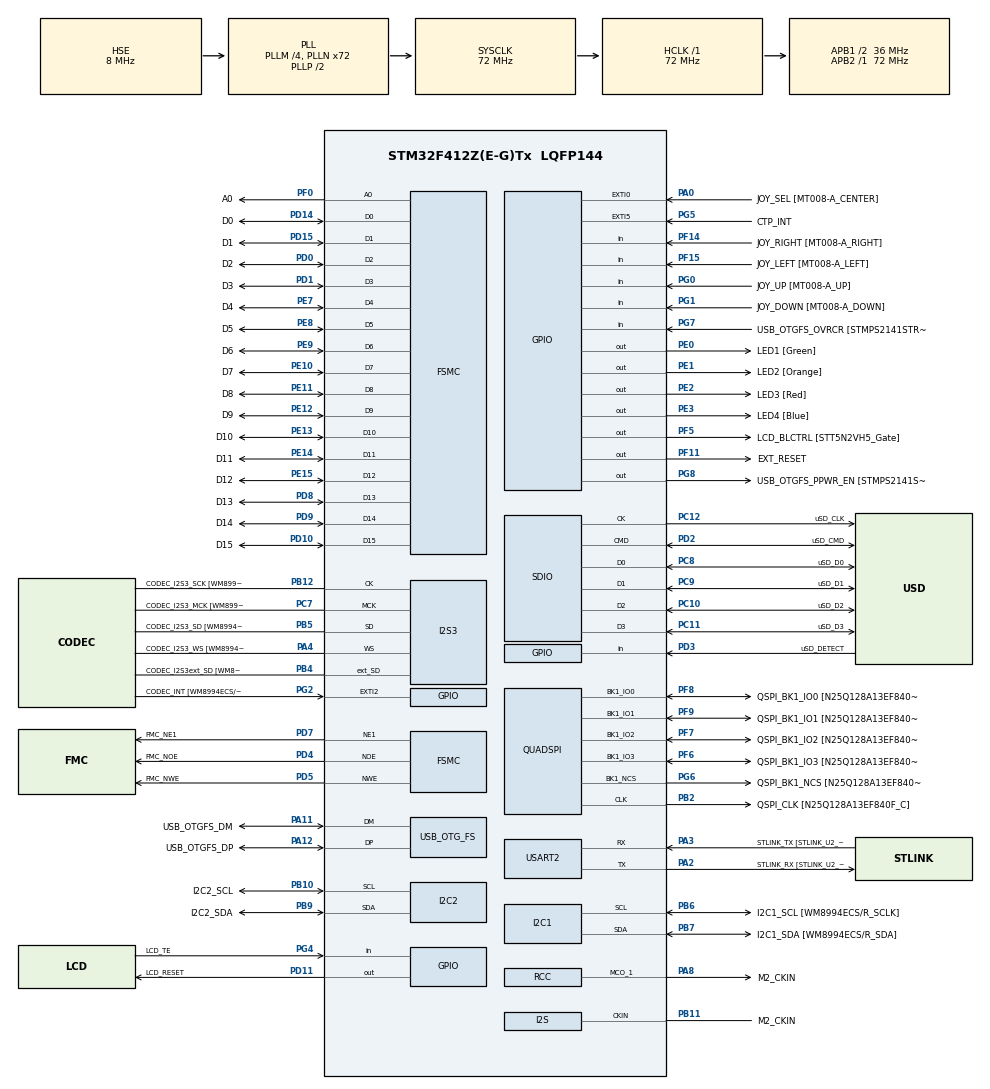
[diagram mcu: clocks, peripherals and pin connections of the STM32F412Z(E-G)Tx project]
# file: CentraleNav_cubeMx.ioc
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I2S3.AudioFreq=I2S_AUDIOFREQ_32K
I2S3.ErrorAudioFreq=1.72 %
I2S3.FullDuplexMode=I2S_FULLDUPLEXMODE_ENABLE
I2S3.Instance=SPI$Index
I2S3.RealAudioFreq=32.552 KHz
I2S3.VirtualMode=I2S_MODE_MASTER
Mcu.Family=STM32F4
Mcu.Name=STM32F412Z(E-G)Tx
Mcu.Package=LQFP144
NVIC.OTG_FS_IRQn=true\:0\:0\:false\:false\:true\:true\:true
NVIC.PriorityGroup=NVIC_PRIORITYGROUP_4
NVIC.TIM1_TRG_COM_TIM11_IRQn=true\:0\:0\:false\:false\:true\:true\:true
NVIC.TIM8_BRK_TIM12_IRQn=true\:0\:0\:false\:false\:true\:true\:true
NVIC.TIM8_UP_TIM13_IRQn=true\:0\:0\:false\:false\:true\:true\:true
PA0.GPIO_Label=JOY_SEL [MT008-A_CENTER]
PA0.Signal=GPXTI0
PA10.GPIO_Label=USB_OTGFS_ID
PA10.Signal=USB_OTG_FS_ID
PA11.GPIO_Label=USB_OTGFS_DM
PA11.Mode=Host_Only
PA11.Signal=USB_OTG_FS_DM
PA12.GPIO_Label=USB_OTGFS_DP
PA12.Mode=Host_Only
PA12.Signal=USB_OTG_FS_DP
PA13.GPIO_Label=SWDIO
PA13.Mode=Serial_Wire
PA13.Signal=SYS_JTMS-SWDIO
PA14.GPIO_Label=SWCLK
PA14.Mode=Serial_Wire
PA14.Signal=SYS_JTCK-SWCLK
PA2.GPIO_Label=STLINK_RX [STLINK_U2_RX]
PA2.Mode=Asynchronous
PA2.Signal=USART2_TX
PA3.GPIO_Label=STLINK_TX [STLINK_U2_TX]
PA3.Mode=Asynchronous
PA3.Signal=USART2_RX
PA4.GPIO_Label=CODEC_I2S3_WS [WM8994ECS/R_LRCLK1]
PA4.Mode=Full_Duplex_Master
PA4.Signal=I2S3_WS
PA8.GPIO_Label=M2_CKIN
PA8.Mode=Clock-out-1
PA8.Signal=RCC_MCO_1
PA9.GPIO_Label=USB_OTGFS_VBUS
PA9.Signal=USB_OTG_FS_VBUS
PB1.GPIO_Label=DFSDM_DATIN0 [MP34DT01TR_DOUT]
PB1.Signal=S_DATAIN0DFSDM1
PB10.GPIO_Label=I2C2_SCL
PB10.Mode=I2C
PB10.Signal=I2C2_SCL
PB11.GPIO_Label=M2_CKIN
PB11.Mode=Audio_ClockIn
PB11.Signal=I2S_CKIN
PB12.GPIO_Label=CODEC_I2S3_SCK [WM8994ECS/R_BCLK1]
PB12.Mode=Full_Duplex_Master
PB12.Signal=I2S3_CK
PB2.GPIO_Label=QSPI_CLK [N25Q128A13EF840F_C]
PB2.Mode=Single Bank 1
PB2.Signal=QUADSPI_CLK
PB3.GPIO_Label=SWO
PB3.Signal=SYS_JTDO-SWO
PB4.GPIO_Label=CODEC_I2S3ext_SD [WM8994ECS/R_ACDAT1]
PB4.Mode=Full_Duplex_Master
PB4.Signal=I2S3_ext_SD
PB5.GPIO_Label=CODEC_I2S3_SD [WM8994ECS/R_DACDAT1]
PB5.Mode=Full_Duplex_Master
PB5.Signal=I2S3_SD
PB6.GPIO_Label=I2C1_SCL [WM8994ECS/R_SCLK]
PB6.Mode=I2C
PB6.Signal=I2C1_SCL
PB7.GPIO_Label=I2C1_SDA [WM8994ECS/R_SDA]
PB7.Mode=I2C
PB7.Signal=I2C1_SDA
PB9.GPIO_Label=I2C2_SDA
PB9.Mode=I2C
PB9.Signal=I2C2_SDA
PC10.GPIO_Label=uSD_D2
PC10.Mode=SD_4_bits_Wide_bus
PC10.Signal=SDIO_D2
PC11.GPIO_Label=uSD_D3
PC11.Mode=SD_4_bits_Wide_bus
PC11.Signal=SDIO_D3
PC12.GPIO_Label=uSD_CLK
PC12.Mode=SD_4_bits_Wide_bus
PC12.Signal=SDIO_CK
PC14-OSC32_IN.Mode=LSE-External-Oscillator
PC14-OSC32_IN.Signal=RCC_OSC32_IN
PC15-OSC32_OUT.Mode=LSE-External-Oscillator
PC15-OSC32_OUT.Signal=RCC_OSC32_OUT
PC2.GPIO_Label=DFSDM_CKOUT [MP34DT01TR_CLK]
PC2.Signal=S_CKOUTDFSDM1
PC7.GPIO_Label=CODEC_I2S3_MCK [WM8994ECS/R_MCLK1]
PC7.Mode=Master_Clock_Activated
PC7.Signal=I2S3_MCK
PC8.GPIO_Label=uSD_D0
PC8.Mode=SD_4_bits_Wide_bus
PC8.Signal=SDIO_D0
PC9.GPIO_Label=uSD_D1
PC9.Mode=SD_4_bits_Wide_bus
PC9.Signal=SDIO_D1
PD0.GPIO_Label=D2
PD0.Signal=FSMC_D2_DA2
PD1.GPIO_Label=D3
PD1.Signal=FSMC_D3_DA3
PD10.GPIO_Label=D15
PD10.Signal=FSMC_D15_DA15
PD11.GPIO_Label=LCD_RESET
PD11.Signal=GPIO_Output
PD14.GPIO_Label=D0
PD14.Signal=FSMC_D0_DA0
PD15.GPIO_Label=D1
PD15.Signal=FSMC_D1_DA1
PD2.GPIO_Label=uSD_CMD
PD2.Mode=SD_4_bits_Wide_bus
PD2.Signal=SDIO_CMD
PD3.GPIO_Label=uSD_DETECT
PD3.Signal=GPIO_Input
PD4.GPIO_Label=FMC_NOE
PD4.Signal=FSMC_NOE
PD5.GPIO_Label=FMC_NWE
PD5.Signal=FSMC_NWE
PD7.GPIO_Label=FMC_NE1
PD7.Mode=NorPsramChipSelect1_1
PD7.Signal=FSMC_NE1
PD8.GPIO_Label=D13
PD8.Signal=FSMC_D13_DA13
PD9.GPIO_Label=D14
PD9.Signal=FSMC_D14_DA14
PE0.GPIO_Label=LED1 [Green]
PE0.GPIO_ModeDefaultOutputPP=GPIO_MODE_OUTPUT_OD
PE0.Signal=GPIO_Output
PE1.GPIO_Label=LED2 [Orange]
PE1.GPIO_ModeDefaultOutputPP=GPIO_MODE_OUTPUT_OD
PE1.Signal=GPIO_Output
PE10.GPIO_Label=D7
PE10.Signal=FSMC_D7_DA7
PE11.GPIO_Label=D8
PE11.Signal=FSMC_D8_DA8
PE12.GPIO_Label=D9
PE12.Signal=FSMC_D9_DA9
PE13.GPIO_Label=D10
PE13.Signal=FSMC_D10_DA10
PE14.GPIO_Label=D11
PE14.Signal=FSMC_D11_DA11
PE15.GPIO_Label=D12
PE15.Signal=FSMC_D12_DA12
PE2.GPIO_Label=LED3 [Red]
PE2.GPIO_ModeDefaultOutputPP=GPIO_MODE_OUTPUT_OD
PE2.Signal=GPIO_Output
PE3.GPIO_Label=LED4 [Blue]
PE3.GPIO_ModeDefaultOutputPP=GPIO_MODE_OUTPUT_OD
PE3.Signal=GPIO_Output
PE4.GPIO_Label=DFSDM_DATIN3 [MP23DB01MM_DOUT]
PE4.Signal=S_DATAIN3DFSDM1
PE7.GPIO_Label=D4
PE7.Signal=FSMC_D4_DA4
PE8.GPIO_Label=D5
PE8.Signal=FSMC_D5_DA5
PE9.GPIO_Label=D6
PE9.Signal=FSMC_D6_DA6
PF0.GPIO_Label=A0
PF0.Signal=FSMC_A0
PF11.GPIO_Label=EXT_RESET
PF11.Signal=GPIO_Output
PF14.GPIO_Label=JOY_RIGHT [MT008-A_RIGHT]
PF14.Signal=GPIO_Input
PF15.GPIO_Label=JOY_LEFT [MT008-A_LEFT]
PF15.Signal=GPIO_Input
PF5.GPIO_Label=LCD_BLCTRL [STT5N2VH5_Gate]
PF5.Signal=GPIO_Output
PF6.GPIO_Label=QSPI_BK1_IO3 [N25Q128A13EF840F_DQ3]
PF6.Mode=Single Bank 1
PF6.Signal=QUADSPI_BK1_IO3
PF7.GPIO_Label=QSPI_BK1_IO2 [N25Q128A13EF840F_DQ2]
PF7.Mode=Single Bank 1
PF7.Signal=QUADSPI_BK1_IO2
PF8.GPIO_Label=QSPI_BK1_IO0 [N25Q128A13EF840F_DQ0]
PF8.Mode=Single Bank 1
PF8.Signal=QUADSPI_BK1_IO0
PF9.GPIO_Label=QSPI_BK1_IO1 [N25Q128A13EF840F_DQ1]
PF9.Mode=Single Bank 1
PF9.Signal=QUADSPI_BK1_IO1
PG0.GPIO_Label=JOY_UP [MT008-A_UP]
PG0.Signal=GPIO_Input
PG1.GPIO_Label=JOY_DOWN [MT008-A_DOWN]
PG1.Signal=GPIO_Input
PG2.GPIO_Label=CODEC_INT [WM8994ECS/R_ADCLRCLK1/GPIO1]
PG2.Signal=GPXTI2
PG4.GPIO_Label=LCD_TE
PG4.Signal=GPIO_Input
PG5.GPIO_Label=CTP_INT
PG5.Signal=GPXTI5
PG6.GPIO_Label=QSPI_BK1_NCS [N25Q128A13EF840F_S]
PG6.Mode=Single Bank 1
PG6.Signal=QUADSPI_BK1_NCS
PG7.GPIO_Label=USB_OTGFS_OVRCR [STMPS2141STR_FAULT]
PG7.Signal=GPIO_Input
PG8.GPIO_Label=USB_OTGFS_PPWR_EN [STMPS2141STR_EN]
PG8.GPIO_ModeDefaultOutputPP=GPIO_MODE_OUTPUT_OD
PG8.PinState=GPIO_PIN_SET
PG8.Signal=GPIO_Output
PH0\ -\ OSC_IN.GPIO_Label=STLK_MCO
PH0\ -\ OSC_IN.Mode=HSE-External-Clock-Source
PH0\ -\ OSC_IN.Signal=RCC_OSC_IN
PH1\ -\ OSC_OUT.Mode=HSE-External-Clock-Source
PH1\ -\ OSC_OUT.Signal=RCC_OSC_OUT
ProjectManager.HeapSize=0x200
ProjectManager.StackSize=0x400
ProjectManager.TargetToolchain=TrueSTUDIO
RCC.48MHZClocksFreq_Value=48000000
RCC.AHBFreq_Value=72000000
RCC.APB1CLKDivider=RCC_HCLK_DIV2
RCC.APB1Freq_Value=36000000
RCC.APB1TimFreq_Value=72000000
RCC.APB2Freq_Value=72000000
RCC.APB2TimFreq_Value=72000000
RCC.CortexFreq_Value=72000000
RCC.HCLKFreq_Value=72000000
RCC.HSE_VALUE=8000000
RCC.HSI_VALUE=16000000
RCC.PLLI2SM=4
RCC.PLLI2SN=50
RCC.PLLM=4
RCC.PLLN=72
RCC.PLLQ=3
RCC.SYSCLKFreq_VALUE=72000000
RCC.SYSCLKSource=RCC_SYSCLKSOURCE_PLLCLK
RCC.USBFreq_Value=48000000
RCC.VCOOutputFreq_Value=144000000
SDIO.WideMode=SDIO_BUS_WIDE_4B
SH.FSMC_A0.0=FSMC_A0,A0_1
SH.FSMC_D0_DA0.0=FSMC_D0,16b-d1
SH.FSMC_D10_DA10.0=FSMC_D10,16b-d1
SH.FSMC_D11_DA11.0=FSMC_D11,16b-d1
SH.FSMC_D12_DA12.0=FSMC_D12,16b-d1
SH.FSMC_D13_DA13.0=FSMC_D13,16b-d1
SH.FSMC_D14_DA14.0=FSMC_D14,16b-d1
SH.FSMC_D15_DA15.0=FSMC_D15,16b-d1
SH.FSMC_D1_DA1.0=FSMC_D1,16b-d1
SH.FSMC_D2_DA2.0=FSMC_D2,16b-d1
SH.FSMC_D3_DA3.0=FSMC_D3,16b-d1
SH.FSMC_D4_DA4.0=FSMC_D4,16b-d1
SH.FSMC_D5_DA5.0=FSMC_D5,16b-d1
SH.FSMC_D6_DA6.0=FSMC_D6,16b-d1
SH.FSMC_D7_DA7.0=FSMC_D7,16b-d1
SH.FSMC_D8_DA8.0=FSMC_D8,16b-d1
SH.FSMC_D9_DA9.0=FSMC_D9,16b-d1
SH.FSMC_NOE.0=FSMC_NOE,Lcd1
SH.FSMC_NWE.0=FSMC_NWE,Lcd1
SH.S_CKOUTDFSDM1.0=DFSDM1_CKOUT
SH.S_DATAIN0DFSDM1.0=DFSDM1_DATIN0
SH.S_DATAIN3DFSDM1.0=DFSDM1_DATIN3
TIM11.ClockDivision=TIM_CLOCKDIVISION_DIV1
TIM11.Period=4000
TIM11.Prescaler=17999
TIM12.ClockDivision=TIM_CLOCKDIVISION_DIV1
TIM12.Period=400
TIM12.Prescaler=17999
TIM13.ClockDivision=TIM_CLOCKDIVISION_DIV1
TIM13.Period=40
TIM13.Prescaler=17999
USART2.VirtualMode=VM_ASYNC
USB_HOST.BSP.number=1
USB_HOST.USBH_HandleTypeDef=hUsbHostFS
USB_HOST.VirtualModeFS=Cdc
USB_HOST0.BSP.STBoard=false
USB_HOST0.BSP.api=Unknown
USB_HOST0.BSP.i2caddr=0
USB_HOST0.BSP.i2creg=0
USB_HOST0.BSP.instance=PG8
USB_HOST0.BSP.ip=GPIO
USB_HOST0.BSP.mode=Output
USB_HOST0.BSP.name=Drive_VBUS_FS
USB_HOST0.BSP.solution=PG8
USB_OTG_FS.VirtualMode=Host_Only
USB_OTG_FS.phy_itface=HCD_PHY_EMBEDDED
VP_TIM11_VS_ClockSourceINT.Mode=Enable_Timer
VP_TIM12_VS_ClockSourceINT.Mode=Internal
VP_TIM13_VS_ClockSourceINT.Mode=Enable_Timer
VP_USB_HOST_VS_USB_HOST_CDC_FS.Mode=CDC_FS
board=STM32F412G-DISCO

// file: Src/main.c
/* USER CODE BEGIN Header */
/**
  ******************************************************************************
  * @file           : main.c
  * @brief          : Main program body
  ******************************************************************************
  * @attention
  *
  * <h2><center>&copy; Copyright (c) 2019 STMicroelectronics.
  * All rights reserved.</center></h2>
  *
  * This software component is licensed by ST under Ultimate Liberty license
  * SLA0044, the "License"; You may not use this file except in compliance with
  * the License. You may obtain a copy of the License at:
  *                             www.st.com/SLA0044
  *
  ******************************************************************************
  */
/* USER CODE END Header */

#include "main.h"
#include "i2c.h"
#include "i2s.h"
#include "quadspi.h"
#include "sdio.h"
#include "tim.h"
#include "usart.h"
#include "usb_host.h"
#include "gpio.h"
#include "fsmc.h"

/* USER CODE BEGIN Includes */
#include <stdio.h>

#include "../user/init.h"
#include "../user/loop.h"
/* USER CODE END Includes */

void SystemClock_Config(void);
void MX_USB_HOST_Process(void);

int main(void)
{

  /* MCU Configuration--------------------------------------------------------*/

  /* Reset of all peripherals, Initializes the Flash interface and the Systick. */
  HAL_Init();

  /* Configure the system clock */
  SystemClock_Config();

  /* Initialize all configured peripherals */
  MX_GPIO_Init();
  MX_FSMC_Init();
  MX_I2C1_Init();
  MX_I2C2_Init();
  MX_I2S3_Init();
  MX_QUADSPI_Init();
  MX_SDIO_SD_Init();
  MX_USART2_UART_Init();
  MX_USB_HOST_Init();
  MX_TIM12_Init();
  MX_TIM11_Init();
  MX_TIM13_Init();
  /* USER CODE BEGIN 2 */
  init();
  /* USER CODE END 2 */

  /* Infinite loop */
  while (1)
  {
    MX_USB_HOST_Process();

    /* USER CODE BEGIN 3 */
	  loop();
  }
  /* USER CODE END 3 */
}

void SystemClock_Config(void)
{
  RCC_OscInitTypeDef RCC_OscInitStruct = {0};
  RCC_ClkInitTypeDef RCC_ClkInitStruct = {0};
  RCC_PeriphCLKInitTypeDef PeriphClkInitStruct = {0};

  /** Configure the main internal regulator output voltage
  */
  __HAL_RCC_PWR_CLK_ENABLE();
  __HAL_PWR_VOLTAGESCALING_CONFIG(PWR_REGULATOR_VOLTAGE_SCALE1);
  /** Initializes the CPU, AHB and APB busses clocks
  */
  RCC_OscInitStruct.OscillatorType = RCC_OSCILLATORTYPE_HSI|RCC_OSCILLATORTYPE_HSE;
  RCC_OscInitStruct.HSEState = RCC_HSE_BYPASS;
  RCC_OscInitStruct.HSIState = RCC_HSI_ON;
  RCC_OscInitStruct.HSICalibrationValue = RCC_HSICALIBRATION_DEFAULT;
  RCC_OscInitStruct.PLL.PLLState = RCC_PLL_ON;
  RCC_OscInitStruct.PLL.PLLSource = RCC_PLLSOURCE_HSE;
  RCC_OscInitStruct.PLL.PLLM = 4;
  RCC_OscInitStruct.PLL.PLLN = 72;
  RCC_OscInitStruct.PLL.PLLP = RCC_PLLP_DIV2;
  RCC_OscInitStruct.PLL.PLLQ = 3;
  RCC_OscInitStruct.PLL.PLLR = 2;
  if (HAL_RCC_OscConfig(&RCC_OscInitStruct) != HAL_OK)
  {
    Error_Handler();
  }
  /** Initializes the CPU, AHB and APB busses clocks
  */
  RCC_ClkInitStruct.ClockType = RCC_CLOCKTYPE_HCLK|RCC_CLOCKTYPE_SYSCLK
                              |RCC_CLOCKTYPE_PCLK1|RCC_CLOCKTYPE_PCLK2;
  RCC_ClkInitStruct.SYSCLKSource = RCC_SYSCLKSOURCE_PLLCLK;
  RCC_ClkInitStruct.AHBCLKDivider = RCC_SYSCLK_DIV1;
  RCC_ClkInitStruct.APB1CLKDivider = RCC_HCLK_DIV2;
  RCC_ClkInitStruct.APB2CLKDivider = RCC_HCLK_DIV1;

  if (HAL_RCC_ClockConfig(&RCC_ClkInitStruct, FLASH_LATENCY_2) != HAL_OK)
  {
    Error_Handler();
  }
  PeriphClkInitStruct.PeriphClockSelection = RCC_PERIPHCLK_I2S_APB1|RCC_PERIPHCLK_SDIO
                              |RCC_PERIPHCLK_CLK48;
  PeriphClkInitStruct.PLLI2S.PLLI2SN = 50;
  PeriphClkInitStruct.PLLI2S.PLLI2SM = 4;
  PeriphClkInitStruct.PLLI2S.PLLI2SR = 2;
  PeriphClkInitStruct.PLLI2S.PLLI2SQ = 2;
  PeriphClkInitStruct.Clk48ClockSelection = RCC_CLK48CLKSOURCE_PLLQ;
  PeriphClkInitStruct.SdioClockSelection = RCC_SDIOCLKSOURCE_CLK48;
  PeriphClkInitStruct.PLLI2SSelection = RCC_PLLI2SCLKSOURCE_PLLSRC;
  PeriphClkInitStruct.I2sApb1ClockSelection = RCC_I2SAPB1CLKSOURCE_PLLI2S;
  if (HAL_RCCEx_PeriphCLKConfig(&PeriphClkInitStruct) != HAL_OK)
  {
    Error_Handler();
  }
  HAL_RCC_MCOConfig(RCC_MCO1, RCC_MCO1SOURCE_HSI, RCC_MCODIV_1);
}

void Error_Handler(void)
{
}

/************************ (C) COPYRIGHT STMicroelectronics *****END OF FILE****/
